# S6E1C3xB register map
Vendor: Cypress; File version: 2.0
CPU: CM0PLUS r0p1, little endian, no MPU, no FPU, 2 interrupt priority bits
Registers are 32-bit, read-write, reset 0x0 unless marked. A register's access mark holds for its fields unless they carry their own. Offsets are from the block's base; [hi:lo] are bit positions; {n}, {i} and the like mark numbered series.

## MTB_DWT — Micro Trace Buffer Data Watchpoint and Trace Registers
Base 0xF0001000
0x00 CMP_ADDR_START — MTB_DWT Address Compare Start trace Register
  [31:0] ADCMP_STA — MTB_DWT address comparison start trace bits
0x04 CMP_DATA_START — MTB_DWT Data Compare Start trace Register
  [31:0] DTCMP_STA — MTB_DWT data comparison start trace bits
0x08 CMP_MASK_START — MTB_DWT Mask Data Compare Start Trace Register
  [31:0] MSK_STA — MTB_DWT data compare start trace register mask bits
0x10 CMP_ADDR_STOP — MTB_DWT Address Compare Stop trace Register
  [31:0] ADCMP_STO — MTB_DWT address comparison stop trace bits
0x14 CMP_DATA_STOP — MTB_DWT Data Compare Stop trace Register
  [31:0] DTCMP_STO — MTB_DWT data comparison stop trace bits
0x18 CMP_MASK_STOP — MTB_DWT Mask Data Compare Stop Trace Register
  [31:0] MSK_STO — MTB_DWT data compare stop trace register mask bits
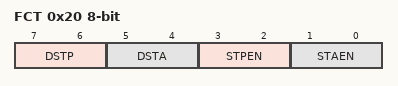
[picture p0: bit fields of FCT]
0x20 FCT 8-bit — MTB_DWT Function Register
  [7:6] DSTP — Data size stop bits
  [5:4] DSTA — Data size start bits
  [3:2] STPEN — Enable MTB_DWT stop MTB function bits
  [1:0] STAEN — Enable MTB_DWT start MTB function bits
{0xFC0+4i} PID{i} ro (i=4..7) — Peripheral ID{i} Register
  [31:0] PERID — Peripheral ID bits
0xFE0 PID0 ro reset 0x16 — Peripheral ID0 Register
  [31:0] PERID — Peripheral ID bits
0xFE4 PID1 ro reset 0x48 — Peripheral ID1 Register
  [31:0] PERID — Peripheral ID bits
0xFE8 PID2 ro reset 0x8 — Peripheral ID2 Register
  [31:0] PERID — Peripheral ID bits
0xFEC PID3 ro — Peripheral ID3 Register
  [31:0] PERID — Peripheral ID bits
0xFF0 CID0 ro reset 0xD — Component ID0 Register
  [31:0] CPNTID — Component ID bits
0xFF4 CID1 ro reset 0x90 — Component ID1 Register
  [31:0] CPNTID — Component ID bits
0xFF8 CID2 ro reset 0x5 — Component ID2 Register
  [31:0] CPNTID — Component ID bits
0xFFC CID3 ro reset 0xB1 — Component ID3 Register
  [31:0] CPNTID — Component ID bits

## FASTIO — Fast GPIO Registers
Base 0xF8000000
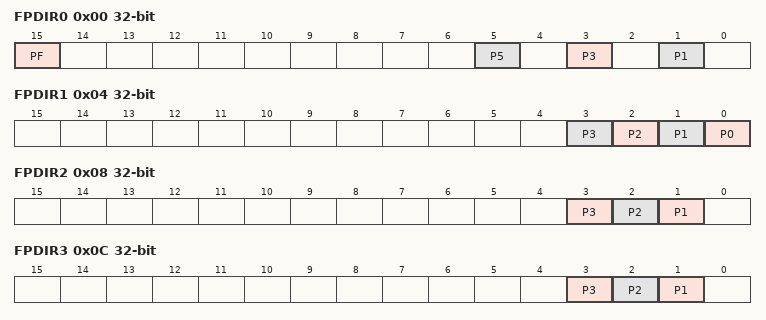
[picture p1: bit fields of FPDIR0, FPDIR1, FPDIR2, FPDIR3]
0x00 FPDIR0 ro — Fast GPIO Input Data Register 0
  [15] PF rw — Bit15 of FPDIR0
  [5] P5 rw — Bit5 of FPDIR0
  [3] P3 rw — Bit3 of FPDIR0
  [1] P1 rw — Bit1 of FPDIR0
0x04 FPDIR1 ro — Fast GPIO Input Data Register 1
  [n] P{n} rw (n=0..3) — Bit{n} of FPDIR1
0x08 FPDIR2 ro — Fast GPIO Input Data Register 2
  [3] P3 rw — Bit3 of FPDIR2
  [2] P2 rw — Bit2 of FPDIR2
  [1] P1 rw — Bit1 of FPDIR2
0x0C FPDIR3 ro — Fast GPIO Input Data Register 3
  [3] P3 rw — Bit3 of FPDIR3
  [2] P2 rw — Bit2 of FPDIR3
  [1] P1 rw — Bit1 of FPDIR3
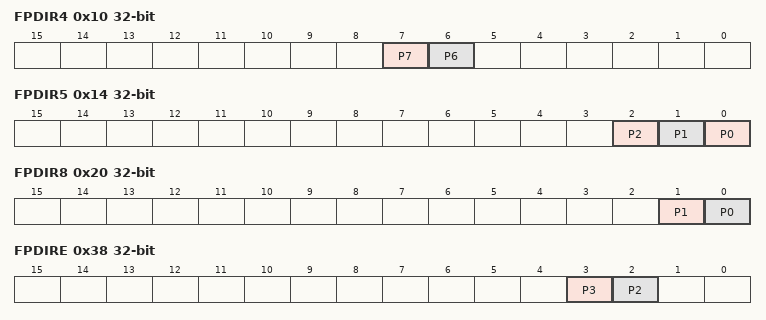
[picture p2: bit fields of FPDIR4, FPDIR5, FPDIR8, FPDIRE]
0x10 FPDIR4 ro — Fast GPIO Input Data Register 4
  [7] P7 rw — Bit7 of FPDIR4
  [6] P6 rw — Bit6 of FPDIR4
0x14 FPDIR5 ro — Fast GPIO Input Data Register 5
  [2] P2 rw — Bit2 of FPDIR5
  [1] P1 rw — Bit1 of FPDIR5
  [0] P0 rw — Bit0 of FPDIR5
0x18 FPDIR6 ro — Fast GPIO Input Data Register 6
  [0] P0 rw — Bit0 of FPDIR6
0x1C FPDIR7 ro reset not defined — Fast GPIO Input Data Register 7
0x20 FPDIR8 ro — Fast GPIO Input Data Register 8
  [1] P1 rw — Bit1 of FPDIR8
  [0] P0 rw — Bit0 of FPDIR8
0x24 FPDIR9 ro reset not defined — Fast GPIO Input Data Register 9
0x28 FPDIRA ro reset not defined — Fast GPIO Input Data Register A
0x2C FPDIRB ro reset not defined — Fast GPIO Input Data Register B
0x30 FPDIRC ro reset not defined — Fast GPIO Input Data Register C
0x34 FPDIRD ro reset not defined — Fast GPIO Input Data Register D
0x38 FPDIRE ro — Fast GPIO Input Data Register E
  [3] P3 rw — Bit3 of FPDIRE
  [2] P2 rw — Bit2 of FPDIRE
0x3C FPDIRF ro reset not defined — Fast GPIO Input Data Register F
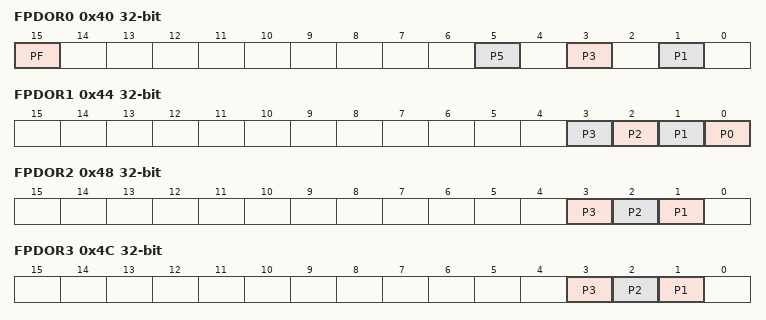
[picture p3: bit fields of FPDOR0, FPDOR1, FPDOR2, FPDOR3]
0x40 FPDOR0 — Fast GPIO Output Data Register 0
  [15] PF — Bit15 of FPDOR0
  [5] P5 — Bit5 of FPDOR0
  [3] P3 — Bit3 of FPDOR0
  [1] P1 — Bit1 of FPDOR0
0x44 FPDOR1 — Fast GPIO Output Data Register 1
  [n] P{n} (n=0..3) — Bit{n} of FPDOR1
0x48 FPDOR2 — Fast GPIO Output Data Register 2
  [3] P3 — Bit3 of FPDOR2
  [2] P2 — Bit2 of FPDOR2
  [1] P1 — Bit1 of FPDOR2
0x4C FPDOR3 — Fast GPIO Output Data Register 3
  [3] P3 — Bit3 of FPDOR3
  [2] P2 — Bit2 of FPDOR3
  [1] P1 — Bit1 of FPDOR3
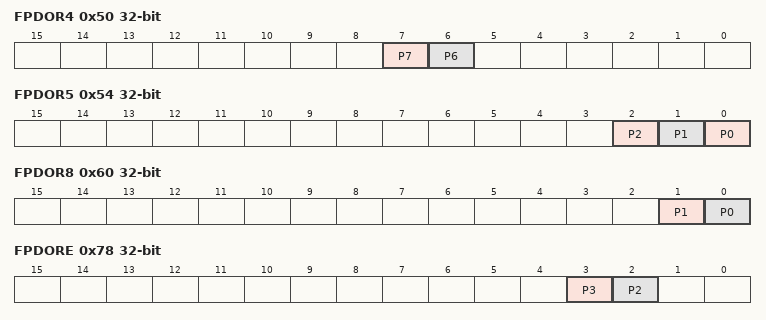
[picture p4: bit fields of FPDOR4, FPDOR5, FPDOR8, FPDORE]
0x50 FPDOR4 — Fast GPIO Output Data Register 4
  [7] P7 — Bit7 of FPDOR4
  [6] P6 — Bit6 of FPDOR4
0x54 FPDOR5 — Fast GPIO Output Data Register 5
  [2] P2 — Bit2 of FPDOR5
  [1] P1 — Bit1 of FPDOR5
  [0] P0 — Bit0 of FPDOR5
0x58 FPDOR6 — Fast GPIO Output Data Register 6
  [0] P0 — Bit0 of FPDOR6
0x5C FPDOR7 reset not defined — Fast GPIO Output Data Register 7
0x60 FPDOR8 — Fast GPIO Output Data Register 8
  [1] P1 — Bit1 of FPDOR8
  [0] P0 — Bit0 of FPDOR8
0x64 FPDOR9 reset not defined — Fast GPIO Output Data Register 9
0x68 FPDORA reset not defined — Fast GPIO Output Data Register A
0x6C FPDORB reset not defined — Fast GPIO Output Data Register B
0x70 FPDORC reset not defined — Fast GPIO Output Data Register C
0x74 FPDORD reset not defined — Fast GPIO Output Data Register D
0x78 FPDORE — Fast GPIO Output Data Register E
  [3] P3 — Bit3 of FPDORE
  [2] P2 — Bit2 of FPDORE
0x7C FPDORF reset not defined — Fast GPIO Output Data Register F
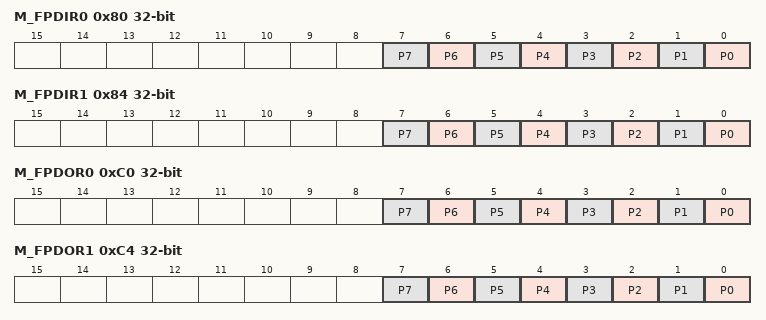
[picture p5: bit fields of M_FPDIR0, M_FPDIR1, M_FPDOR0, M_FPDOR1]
0x80 M_FPDIR0 ro — Mirror Fast GPIO Input Data Register 0
  [n] P{n} rw (n=0..7) — Bit{n} of M_FPDIR0
0x84 M_FPDIR1 ro — Mirror Fast GPIO Input Data Register 1
  [n] P{n} rw (n=0..7) — Bit{n} of M_FPDIR1
0xC0 M_FPDOR0 — Mirror Fast GPIO Output Data Register 0
  [n] P{n} (n=0..7) — Bit{n} of M_FPDOR0
0xC4 M_FPDOR1 — Mirror Fast GPIO Output Data Register 1
  [n] P{n} (n=0..7) — Bit{n} of M_FPDOR1

## VIR — Vector Indicate Registers
Base 0xF8000100
{0x0+4i} VIR{i:02} ro (i=0..31) — Vector Indicate Register {i:02}

## Notices in the file
Copyright (C) 2013-2015, Cypress Semiconductor Corporation. All Rights Reserved.
This software, including source code, documentation and related
materials ( "Software" ), is owned by Cypress Semiconductor
Corporation ( "Cypress" ) and is protected by and subject to worldwide
patent protection (United States and foreign), United States copyright
laws and international treaty provisions. Therefore, you may use this
Software only as provided in the license agreement accompanying the
software package from which you obtained this Software ( "EULA" ).
If no EULA applies, Cypress hereby grants you a personal, nonexclusive,
non-transferable license to copy, modify, and compile the
Software source code solely for use in connection with Cypress's
integrated circuit products. Any reproduction, modification, translation,
compilation, or representation of this Software except as specified
above is prohibited without the express written permission of Cypress.
Disclaimer: THIS SOFTWARE IS PROVIDED AS-IS, WITH NO
WARRANTY OF ANY KIND, EXPRESS OR IMPLIED, INCLUDING,
BUT NOT LIMITED TO, NONINFRINGEMENT, IMPLIED
WARRANTIES OF MERCHANTABILITY AND FITNESS FOR A
PARTICULAR PURPOSE. Cypress reserves the right to make
changes to the Software without notice. Cypress does not assume any
liability arising out of the application or use of the Software or any
product or circuit described in the Software. Cypress does not
authorize its products for use in any products where a malfunction or
failure of the Cypress product may reasonably be expected to result in
significant property damage, injury or death ( "High Risk Product" ). By
including Cypress's product in a High Risk Product, the manufacturer
of such system or application assumes all risk of such use and in doing
so agrees to indemnify Cypress against all liability.
